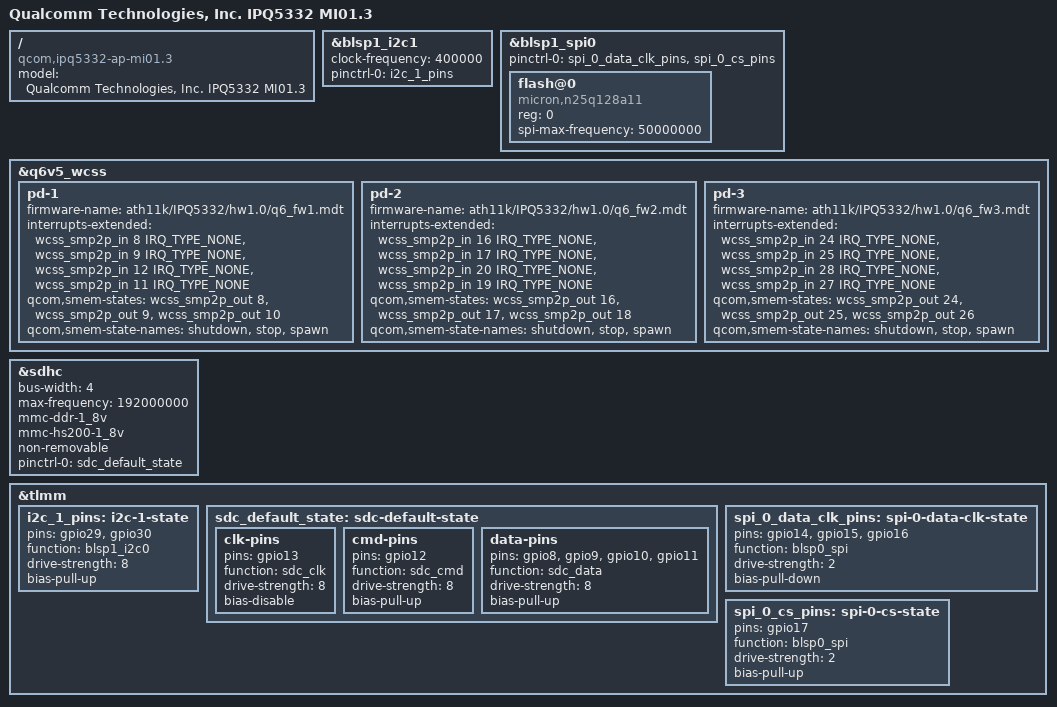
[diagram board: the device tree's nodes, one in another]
// SPDX-License-Identifier: BSD-3-Clause
/*
 * IPQ5332 RDP442 board device tree source
 *
 * Copyright (c) 2023 Qualcomm Innovation Center, Inc. All rights reserved.
 */

/dts-v1/;

#include "ipq5332-rdp-common.dtsi"

/ {
	model = "Qualcomm Technologies, Inc. IPQ5332 MI01.3";
	compatible = "qcom,ipq5332-ap-mi01.3", "qcom,ipq5332";
};

&blsp1_i2c1 {
	clock-frequency  = <400000>;
	pinctrl-0 = <&i2c_1_pins>;
	pinctrl-names = "default";
	status = "okay";
};

&blsp1_spi0 {
	pinctrl-0 = <&spi_0_data_clk_pins &spi_0_cs_pins>;
	pinctrl-names = "default";
	status = "okay";

	flash@0 {
		compatible = "micron,n25q128a11", "jedec,spi-nor";
		reg = <0>;
		#address-cells = <1>;
		#size-cells = <1>;
		spi-max-frequency = <50000000>;
	};
};

&q6v5_wcss {
	pd-1 {
		firmware-name = "ath11k/IPQ5332/hw1.0/q6_fw1.mdt";
		interrupts-extended = <&wcss_smp2p_in 8 IRQ_TYPE_NONE>,
				      <&wcss_smp2p_in 9 IRQ_TYPE_NONE>,
				      <&wcss_smp2p_in 12 IRQ_TYPE_NONE>,
				      <&wcss_smp2p_in 11 IRQ_TYPE_NONE>;
		interrupt-names = "fatal",
				  "ready",
				  "spawn-ack",
				  "stop-ack";

		qcom,smem-states = <&wcss_smp2p_out 8>,
				   <&wcss_smp2p_out 9>,
				   <&wcss_smp2p_out 10>;
		qcom,smem-state-names = "shutdown",
					"stop",
					"spawn";
	};

	pd-2 {
		firmware-name = "ath11k/IPQ5332/hw1.0/q6_fw2.mdt";
		interrupts-extended = <&wcss_smp2p_in 16 IRQ_TYPE_NONE>,
				      <&wcss_smp2p_in 17 IRQ_TYPE_NONE>,
				      <&wcss_smp2p_in 20 IRQ_TYPE_NONE>,
				      <&wcss_smp2p_in 19 IRQ_TYPE_NONE>;
		interrupt-names = "fatal",
				  "ready",
				  "spawn-ack",
				  "stop-ack";

		qcom,smem-states = <&wcss_smp2p_out 16>,
				   <&wcss_smp2p_out 17>,
				   <&wcss_smp2p_out 18>;
		qcom,smem-state-names = "shutdown",
					"stop",
					"spawn";
	};

	pd-3 {
		firmware-name = "ath11k/IPQ5332/hw1.0/q6_fw3.mdt";
		interrupts-extended = <&wcss_smp2p_in 24 IRQ_TYPE_NONE>,
				      <&wcss_smp2p_in 25 IRQ_TYPE_NONE>,
				      <&wcss_smp2p_in 28 IRQ_TYPE_NONE>,
				      <&wcss_smp2p_in 27 IRQ_TYPE_NONE>;
		interrupt-names = "fatal",
				  "ready",
				  "spawn-ack",
				  "stop-ack";

		qcom,smem-states = <&wcss_smp2p_out 24>,
				   <&wcss_smp2p_out 25>,
				   <&wcss_smp2p_out 26>;
		qcom,smem-state-names = "shutdown",
					"stop",
					"spawn";
	};
};

&sdhc {
	bus-width = <4>;
	max-frequency = <192000000>;
	mmc-ddr-1_8v;
	mmc-hs200-1_8v;
	non-removable;
	pinctrl-0 = <&sdc_default_state>;
	pinctrl-names = "default";
	status = "okay";
};

&tlmm {
	i2c_1_pins: i2c-1-state {
		pins = "gpio29", "gpio30";
		function = "blsp1_i2c0";
		drive-strength = <8>;
		bias-pull-up;
	};

	sdc_default_state: sdc-default-state {
		clk-pins {
			pins = "gpio13";
			function = "sdc_clk";
			drive-strength = <8>;
			bias-disable;
		};

		cmd-pins {
			pins = "gpio12";
			function = "sdc_cmd";
			drive-strength = <8>;
			bias-pull-up;
		};

		data-pins {
			pins = "gpio8", "gpio9", "gpio10", "gpio11";
			function = "sdc_data";
			drive-strength = <8>;
			bias-pull-up;
		};
	};

	spi_0_data_clk_pins: spi-0-data-clk-state {
		pins = "gpio14", "gpio15", "gpio16";
		function = "blsp0_spi";
		drive-strength = <2>;
		bias-pull-down;
	};

	spi_0_cs_pins: spi-0-cs-state {
		pins = "gpio17";
		function = "blsp0_spi";
		drive-strength = <2>;
		bias-pull-up;
	};
};
